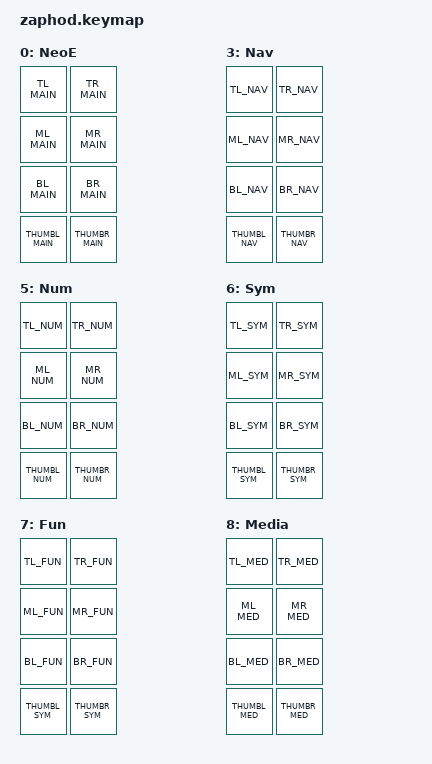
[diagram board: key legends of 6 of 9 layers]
/*
 * Copyright (c) 2021 Pete Johanson
 *
 * SPDX-License-Identifier: MIT
 */

#include <behaviors.dtsi>
#include <dt-bindings/zmk/keys.h>
#include <dt-bindings/zmk/bt.h>
#include <dt-bindings/zmk/outputs.h>

#include "../../../zmk-nodefree-config/helper.h"
#include "./fingers.dtsi"

#include "../../../merlinvn/config.dtsi"
#include "../../../merlinvn/behaviors.dtsi"
#include "../../../merlinvn/keymap.dtsi"
#include "../../../merlinvn/macros.dtsi"
#include "../../../merlinvn/combos.dtsi"

/ {
//    leader_sequences {
//      compatible = "zmk,leader-sequences";
//      seq_esc {
//        key-positions = <0 1>;
//        bindings = <&kp ESC>;
//      };
//    };

//    conditional_layers {
//        compatible = "zmk,conditional-layers";
//        tri_layer {
//            if-layers = <NUM_L SYM_L>;
//            then-layer = <MED_L>;
//        };
//    };

    keymap {
        compatible = "zmk,keymap";

        neo_layer {
            label = "NeoE";
            bindings = <
                TL_MAIN         TR_MAIN
                ML_MAIN         MR_MAIN
                BL_MAIN         BR_MAIN
                THUMBL_MAIN     THUMBR_MAIN
            >;
        };

       qwerty_layer {
            label = "QWERTY";
            bindings = <
                &kp Q      &kp W      &kp E       &kp R          &kp T         &kp Y            &kp U          &kp I           &kp O        &kp P
                &kp A      &kp S      &kp D       &kp F          &kp G         &kp H            &kp J          &kp K           &kp L        &kp SQT
                &kp Z      &kp X      &kp C       &kp V          &kp B         &kp N            &kp M          &kp COMMA       &kp DOT      &kp FSLH
                                                  &kp ESC        &kp SPACE     &kp BSPC         &kp RET
            >;
        };

       vie_layer {
            label = "TELEX";
            bindings = <
                &kp Q       &kp P       &kp M          &kp L           &kp B         &kp Z            &kp R           &kp E          &kp U      &kp FSLH
                &kp I       &kp G       &kp N          &lt NUM_L H     &kp X         &kp F            &kp S           &kp A          &kp W         &kp O
                &lhm LGUI Y &lhm LALT T &lhm LCTRL C   &lhm LSHFT D    &bhm SPACE V         &kp BSPC         &rhm RSHFT J    &rhm RCTRL K &rhm LALT DOT &rhm RGUI COMMA
                                                  &lt NUM_L ESC  &lt NAV_L SPACE     &sl SYM_L   &lt SYM_L RET
            >;
        };

       nav_layer {
            label = "Nav";
            bindings = <
                TL_NAV         TR_NAV
                ML_NAV         MR_NAV
                BL_NAV         BR_NAV
                THUMBL_NAV     THUMBR_NAV
            >;
        };

        other_layer {
            label = "Other";
            bindings = <
                &trans     &trans     &trans      &trans          &trans       &trans           &trans         &trans       &trans       &bt BT_CLR
                &trans     &trans     &trans      &trans          &trans       &trans           &trans         &trans       &trans       &trans
                &trans     &trans     &trans      &trans          &trans       &bt BT_SEL 0     &bt BT_SEL 1   &bt BT_SEL 2 &bt BT_SEL 3 &bt BT_SEL 4
                                                  &trans          &trans       &trans           &trans
            >;
        };

        num_layer {
            label = "Num";
            bindings = <
                TL_NUM         TR_NUM
                ML_NUM         MR_NUM
                BL_NUM         BR_NUM
                THUMBL_NUM     THUMBR_NUM
            >;
        };

        sym_layer {
            label = "Sym";
            bindings = <
                TL_SYM         TR_SYM
                ML_SYM         MR_SYM
                BL_SYM         BR_SYM
                THUMBL_SYM     THUMBR_SYM
            >;
        };

        fun_layer {
            label = "Fun";
            bindings = <
                TL_FUN         TR_FUN
                ML_FUN         MR_FUN
                BL_FUN         BR_FUN
                THUMBL_SYM     THUMBR_SYM
            >;
        };

        media_layer {
            label = "Media";
            bindings = <
                TL_MED         TR_MED
                ML_MED         MR_MED
                BL_MED         BR_MED
                THUMBL_MED     THUMBR_MED
            >;
        };

    };
};

